# iND83213A register map
Vendor: Indiemicro; Series: Rugby; File version: 1.0
CPU: CM0 r0p1, selectable endian, no MPU, no FPU, 4 interrupt priority bits
Registers are 32-bit, read-write, no defined reset value unless marked. A register's access mark holds for its fields unless they carry their own. Offsets are from the block's base; [hi:lo] are bit positions; {n}, {i} and the like mark numbered series.

## WDTA — Watchdog Timer Registers
Base 0x50010200; register names take the prefix WDTA_
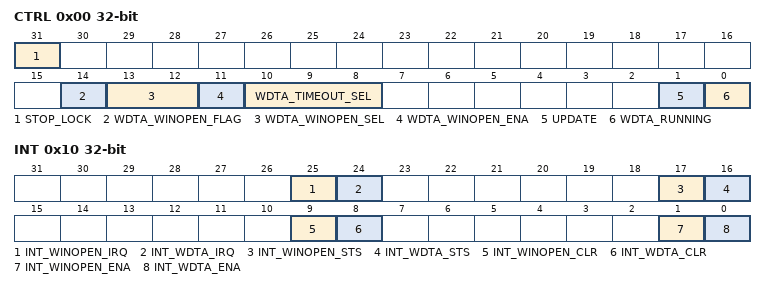
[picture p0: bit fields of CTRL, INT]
0x00 CTRL — Control
  [31] STOP_LOCK — Set Only bit. Set this bit to lock STOP bits.
  [14] WDTA_WINOPEN_FLAG ro — Window open flag. A flag that indicates when the watchdog window is open. It only can be cleared by Reg CLEAR! 0x0: Window is Closed 0x1: Window is Open
  [13:12] WDTA_WINOPEN_SEL — Window Mode open select. Defines the watchdog window open time (the time between the watchdog start and the window open). 0x0: 1/2 * WDT timeout 0x1: 1/4 * WDT timeout 0x2: 1/8 * WDT timeout 0x3: 1/16* WDT timeout
  [11] WDTA_WINOPEN_ENA — Window Mode Enable. Enables Window Mode. 1'b1: Enable the Window mode of Watchdog, if the WDT is cleared before the time window opens, the WDT will issue a system reset. 1'b0: Disable the Window mode of Watchdog.
  [10:8] WDTA_TIMEOUT_SEL — Timeout select. Defines the watchdog timeout period (the time between a clear operation and the next timeout). 0x0: 2^11 * 62.5us ~= 128 ms 0x1: 2^12 * 62.5us ~= 256 ms 0x2: 2^13 * 62.5us ~= 512 ms 0x3: 2^14 * 62.5us ~= 1.024s 0x4: 2^15 * 62.5us ~= 2.048s 0x5: 2^16 * 62.5us ~= 4.096s 0x6: 2^17 * 62.5us ~= 8.192s 0x7: 2^18 * 62.5us ~= 16.384s
  [1] UPDATE — Window Mode Enable. Set to update Analog-Watchdog Configurations. NOTE: DO NOT change the CTRL register when it is high, which indicates there is an update in progress, It gets cleared by the core when the current update is done
  [0] WDTA_RUNNING ro — Analog-Watchdog Running status. A flag that indicates when the Analog-Watchdog timer is enabled. 0x0: Analog-Watchdog timer is stopped and cleared 0x1: Analog-Watchdog timer is running
0x04 STOP
  [31:0] STOP — Stop. Write the *stop* code (0x6da475c3) to this register to reset the timer and disable the watchdog (e.g. during debug). If any other value is written to this register the watchdog will be enabled.
0x08 CLEAR
  [31:0] CLEAR wo — Clear. Write the value 0x3c574ad6 (as a single word access) to reset the watchdog timer. Periodically performing this action is the expected method of preventing the watchdog from timing out (and resetting the MCU).
0x0C CNTVAL — Counter value
  [31:0] CNTVAL ro — Counter value. The instantaneous value of watchdog timeout counter
0x10 INT — WDTA Interrupts
  [25] INT_WINOPEN_IRQ ro — Window Open Interrupt. Set by WDTA timeout
  [24] INT_WDTA_IRQ ro — WDTA timeout Interrupt. Set by WDTA timeout
  [17] INT_WINOPEN_STS ro — Window Open Status. Set by WDTA timeout
  [16] INT_WDTA_STS ro — WDTA timeout Status. Set by WDTA timeout
  [9] INT_WINOPEN_CLR wo — Window Open Interrupt Clear. Autoclear: includes a synchronous reset signal which clears the register on the cycle following write.
  [8] INT_WDTA_CLR wo — WDTA timeout Interrupt Clear. Autoclear: includes a synchronous reset signal which clears the register on the cycle following write.
  [1] INT_WINOPEN_ENA — Window Open Interrupt Enable.
  [0] INT_WDTA_ENA — WDTA timeout Interrupt Enable.

## PWM — Control (and status) registers for the pulse width modulation waveform generator.
Base 0x50011000; register names take the prefix PWM_
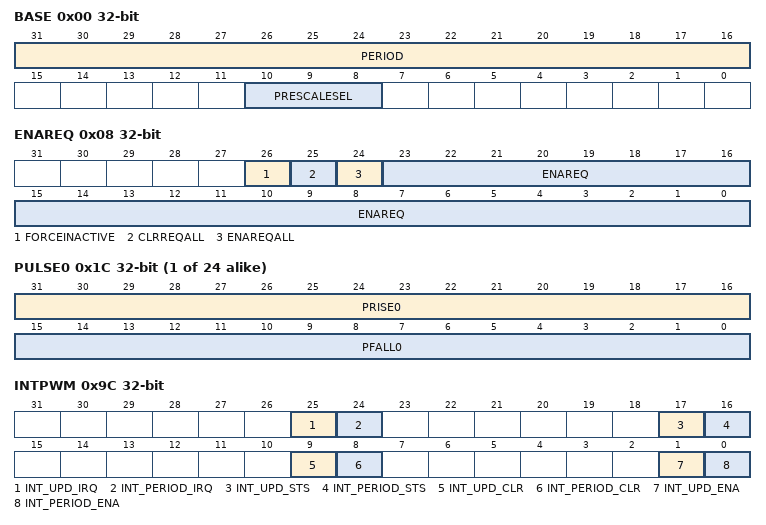
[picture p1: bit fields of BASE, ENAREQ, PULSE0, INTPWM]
0x00 BASE — Base functions
  [31:16] PERIOD — Period. Specifies the period of the output waveform in terms of a number of prescaler output cycles.
  [10:8] PRESCALESEL — Prescaler select. Defines the ratio between the system clock and the clock used for the waveform generator. 0x0: Divide by 1 0x1: Divide by 2 0x2: Divide by 4 0x3: Divide by 8 0x4: Divide by 16 0x5: Divide by 64 0x6: Divide by 256 0x7: Divide by 1024
0x04 PWMCNT — PWM Count Value
  [15:0] PWMCNT — PWM counter value to give a sense about the current period
0x08 ENAREQ — Enable request
  [26] FORCEINACTIVE — Set to force PWM signals return to initial value immediately.
  [25] CLRREQALL wo — Write 1 to clear all ENA_REQ bits; Write 0 has no effects.
  [24] ENAREQALL wo — Write 1 to enable all ENA_REQ bits; Write 0 has no effects.
  [23:0] ENAREQ — Set to enable the waveform generator.
0x0C ENASTS — Enable status
  [23:0] ENASTS ro — Status of enable in the waveform generator.
0x10 INIT — Intial State of Outputs
  [23:0] INIT — Set to initialise the output waveform.
0x14 INV — Invert
  [23:0] INVERT — Set to invert the output waveform.
0x18 UPDATE
  [0] UPDATE — Set to trigger consumption of new PULSE parameters (invert,prescale_sel,period,pulse start & stop). The flag is automatically cleared by the hardware when the settings are consumed, so reading a high value indicates that an update is still pending.
{0x1C+4i} PULSE{i} (i=0..23) — PWM{i} pulse setup
  [31:16] PRISE{i} — Pulse Rise. Specifies the pulse rise of the output waveform in terms of a number of prescaler output cycles. However, if INVERT is set it determines the pulse fall timing.
  [15:0] PFALL{i} — Pulse Fall. Specifies the pulse fall of the output waveform in terms of a number of prescaler output cycles. However, if INVERT is set it determines the pulse rise timing.
0x7C INTPOSEDGENA — PWM posedge interrupt enable
  [23:0] INTPOSEDGENA — Interrupt enable. bit[23:0]: posedge interrupt enable.
0x80 INTNEGEDGENA — PWM negedge interrupt enable
  [23:0] INTNEGEDGENA — Interrupt enable. bit[23:0]: negedge interrupt enable.
0x84 INTPOSEDGCLR — PWM posedge interrupt control
  [23:0] INTPOSEDGCLR wo — Interrupt clear. bit[23:0] : posedge interrupt clear.
0x88 INTNEGEDGCLR — PWM negedge interrupt control
  [23:0] INTNEGEDGCLR wo — Interrupt clear. bit[23:0] : negedge interrupt clear.
0x8C INTPOSEDGSTS — PWM posedge interrupt status
  [23:0] INTPOSEDGSTS ro — Interrupt status. bit[23:0] : posedge interrupt status.
0x90 INTNEGEDGSTS — PWM negedge interrupt status
  [23:0] INTNEGEDGSTS ro — Interrupt status. bit[23:0] : negedge interrupt status.
0x94 INTPOSEDGIRQ — PWM posedge interrupt active
  [23:0] INTPOSEDGIRQ ro — Interrupt active. bit[23:0] : posedge interrupt active.
0x98 INTNEGEDGIRQ — PWM negedge interrupt active
  [23:0] INTNEGEDGIRQ ro — Interrupt active. bit[23:0] : negedge interrupt active.
0x9C INTPWM — PWM interrupt control
  [25] INT_UPD_IRQ ro — Updated Interrupt active.
  [24] INT_PERIOD_IRQ ro — Period Interrupt active.
  [17] INT_UPD_STS ro — Updated Interrupt status.
  [16] INT_PERIOD_STS ro — Period Interrupt status.
  [9] INT_UPD_CLR wo — Updated Interrupt clear.
  [8] INT_PERIOD_CLR wo — Period Interrupt clear.
  [1] INT_UPD_ENA — Updated Interrupt enable.
  [0] INT_PERIOD_ENA — Period Interrupt enable.
